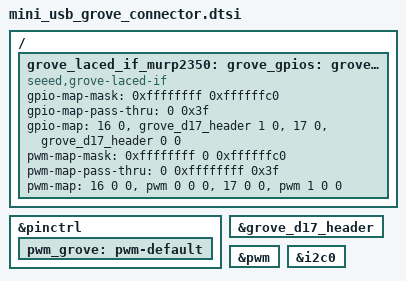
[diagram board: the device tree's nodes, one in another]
/*
 * Copyright (c) 2025 TiaC Systems
 * SPDX-License-Identifier: Apache-2.0
 */

#include <bridle/dt-bindings/seeed_grove_pwms_defaults.h>

&pinctrl {
	pwm_grove: pwm-default {};
};

#include "grove_d17_header.dtsi"

grove_i2c_header: &grove_d17_header {};

/* tweaked labels: Pin 0 isn't the primary data line! */
grove_d16_header: &grove_d17_header {}; /* D16 is on D17 header pin 1 */

/ {
	grove_laced_if_murp2350: grove-laced-if-murp2350 {
		compatible = "seeed,grove-laced-if";

		#gpio-cells = <2>;
		gpio-map-mask = <0xffffffff 0xffffffc0>;
		gpio-map-pass-thru = <0 0x3f>;
		gpio-map =
			/*  0 - GP0:  not wired */
			/*  1 - GP1:  not wired */
			/*  2 - GP2:  not wired */
			/*  3 - GP3:  not wired */
			/*  4 - GP4:  not wired */
			/*  5 - GP5:  not wired */
			/*  6 - GP6:  not wired */
			/*  7 - GP7:  not wired */
			/*  8 - GP8:  not wired */
			/*  9 - GP9:  not wired */
			/* 10 - GP10: not wired */
			/* 11 - GP11: not wired */
			/* 12 - GP12: not wired */
			/* 13 - GP13: not wired */
			/* 14 - GP14: not wired */
			/* 15 - GP15: not wired */
			<16 0 &grove_d17_header 1 0>,	/* GP16: I2C0-SDA as GPIO */
			<17 0 &grove_d17_header 0 0>;	/* GP17: I2C0-SCL as GPIO */
			/* 18 - GP18: not wired */
			/* 19 - GP19: not wired */
			/* 20 - GP20: not wired */
			/* 21 - GP21: not wired */
			/* 22 - GP22: not wired */
			/* 23 - GP23: not wired */
			/* 24 - GP24: not wired */
			/* 25 - GP25: not wired */
			/* 26 - GP26: A0 as GPIO not wired */
			/* 27 - GP27: A1 as GPIO not wired */
			/* 28 - GP28: A2 as GPIO not wired */
			/* 29 - GP29: A3 as GPIO not wired */

		#pwm-cells = <3>;
		pwm-map-mask = <0xffffffff 0 0xffffffc0>;
		pwm-map-pass-thru = <0 0xffffffff 0x3f>;
		pwm-map =
			/*  0 - GP0:  PWM0CHA (0)  not wired */
			/*  1 - GP1:  PWM0CHB (1)  not wired */
			/*  2 - GP2:  PWM1CHA (2)  not wired */
			/*  3 - GP3:  PWM1CHB (3)  not wired */
			/*  4 - GP4:  PWM2CHA (4)  not wired */
			/*  5 - GP5:  PWM2CHB (5)  not wired */
			/*  6 - GP6:  PWM3CHA (6)  not wired */
			/*  7 - GP7:  PWM3CHB (7)  not wired */
			/*  8 - GP8:  PWM4CHA (8)  not wired */
			/*  9 - GP9:  PWM4CHB (9)  not wired */
			/* 10 - GP10: PWM5CHA (10) not wired */
			/* 11 - GP11: PWM5CHB (11) not wired */
			/* 12 - GP12: PWM6CHA (12) not wired */
			/* 13 - GP13: PWM6CHB (13) not wired */
			/* 14 - GP14: PWM7CHA (14) not wired */
			/* 15 - GP15: PWM7CHB (15) not wired */
			<16 0 0 &pwm 0 0 0>,	/* GP16: PWM0CHA (0) */
			<17 0 0 &pwm 1 0 0>;	/* GP17: PWM0CHB (1) */
			/* 18 - GP18: PWM1CHA (2)  not wired */
			/* 19 - GP19: PWM1CHB (3)  not wired */
			/* 20 - GP20: PWM2CHA (4)  not wired */
			/* 21 - GP21: PWM2CHB (5)  not wired */
			/* 22 - GP22: PWM3CHA (6)  not wired */
			/* 23 - GP23: PWM3CHB (7)  not wired */
			/* 24 - GP24: PWM4CHA (8)  not wired */
			/* 25 - GP25: PWM4CHB (9)  not wired */
			/* 26 - GP26: A0 as PWM5CHA (10) not wired */
			/* 27 - GP27: A1 as PWM5CHB (11) not wired */
			/* 28 - GP28: A2 as PWM6CHA (12) not wired */
			/* 29 - GP29: A3 as PWM6CHB (13) not wired */
	};
};

grove_gpios: &grove_laced_if_murp2350 {};
grove_pwms: &grove_laced_if_murp2350 {};

grove_pwm_d16: &pwm {};
grove_pwm_d17: &pwm {};

grove_i2c: &i2c0 {};
